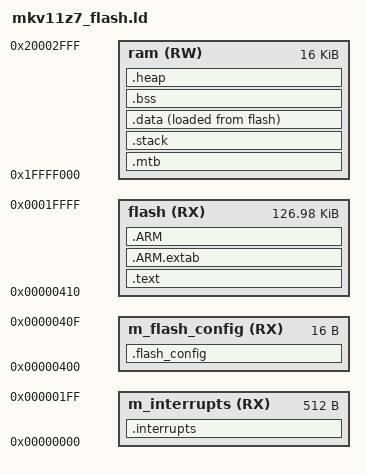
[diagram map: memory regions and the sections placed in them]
/*
** ###################################################################
**     Processors:          MKV11Z128VFM7
**                          MKV11Z128VLC7
**                          MKV11Z128VLF7
**                          MKV11Z128VLH7
**
**     Compiler:            GNU C Compiler
**     Reference manual:    KV11P64M75RM Rev.2, April 2015
**     Version:             rev. 1.0, 2014-12-14
**     Build:               b180911
**
**     Abstract:
**         Linker file for the GNU C Compiler
**
**     Copyright 2016 Freescale Semiconductor, Inc.
**     Copyright 2016-2018 NXP
**     All rights reserved.
**
**     Redistribution and use in source and binary forms, with or without modification,
**     are permitted provided that the following conditions are met:
**
**     1. Redistributions of source code must retain the above copyright notice, this list
**       of conditions and the following disclaimer.
**
**     2. Redistributions in binary form must reproduce the above copyright notice, this
**       list of conditions and the following disclaimer in the documentation and/or
**       other materials provided with the distribution.
**
**     3. Neither the name of the copyright holder nor the names of its
**       contributors may be used to endorse or promote products derived from this
**       software without specific prior written permission.
**
**     THIS SOFTWARE IS PROVIDED BY THE COPYRIGHT HOLDERS AND CONTRIBUTORS "AS IS" AND
**     ANY EXPRESS OR IMPLIED WARRANTIES, INCLUDING, BUT NOT LIMITED TO, THE IMPLIED
**     WARRANTIES OF MERCHANTABILITY AND FITNESS FOR A PARTICULAR PURPOSE ARE
**     DISCLAIMED. IN NO EVENT SHALL THE COPYRIGHT HOLDER OR CONTRIBUTORS BE LIABLE FOR
**     ANY DIRECT, INDIRECT, INCIDENTAL, SPECIAL, EXEMPLARY, OR CONSEQUENTIAL DAMAGES
**     (INCLUDING, BUT NOT LIMITED TO, PROCUREMENT OF SUBSTITUTE GOODS OR SERVICES;
**     LOSS OF USE, DATA, OR PROFITS; OR BUSINESS INTERRUPTION) HOWEVER CAUSED AND ON
**     ANY THEORY OF LIABILITY, WHETHER IN CONTRACT, STRICT LIABILITY, OR TORT
**     (INCLUDING NEGLIGENCE OR OTHERWISE) ARISING IN ANY WAY OUT OF THE USE OF THIS
**     SOFTWARE, EVEN IF ADVISED OF THE POSSIBILITY OF SUCH DAMAGE.
**
**     http:                 www.nxp.com
**     mail:                 support@nxp.com
**
** ###################################################################
*/

/* Entry Point */
ENTRY(Power_On_Reset)

HEAP_SIZE  = DEFINED(__heap_size__)  ? __heap_size__  : 0x0000;
STACK_SIZE = DEFINED(__stack_size__) ? __stack_size__ : 0x0400;

/* Specify the memory areas */
MEMORY
{
  m_interrupts          (RX)  : ORIGIN = 0x00000000, LENGTH = 0x00000200
  m_flash_config        (RX)  : ORIGIN = 0x00000400, LENGTH = 0x00000010
  flash                 (RX)  : ORIGIN = 0x00000410, LENGTH = 0x0001FBF0
  ram                   (RW)  : ORIGIN = 0x1FFFF000, LENGTH = 0x00004000
}

/* Define output sections */
SECTIONS
{
  /* The startup code goes first into internal flash */
  .interrupts :
  {
    . = ALIGN(4);
    KEEP(*(.interupt_vector))     /* Startup code */
    . = ALIGN(4);
  } > m_interrupts

  .flash_config :
  {
    . = ALIGN(4);
    KEEP(*(.FlashConfig))    /* Flash Configuration Field (FCF) */
    . = ALIGN(4);
  } > m_flash_config

  /* The program code and other data goes into internal flash */
  .text :
  {
    . = ALIGN(4);
    *(.text)                 /* .text sections (code) */
    *(.text*)                /* .text* sections (code) */
    *(.rodata)               /* .rodata sections (constants, strings, etc.) */
    *(.rodata*)              /* .rodata* sections (constants, strings, etc.) */
    *(.glue_7)               /* glue arm to thumb code */
    *(.glue_7t)              /* glue thumb to arm code */
    *(.eh_frame)
    KEEP (*(.init))
    KEEP (*(.fini))
    . = ALIGN(4);
  } > flash 

  .ARM.extab :
  {
    *(.ARM.extab* .gnu.linkonce.armextab.*)
  } > flash 

  .ARM :
  {
    __exidx_start = .;
    *(.ARM.exidx*)
    __exidx_end = .;
  } > flash 


  __etext = .;    /* define a global symbol at end of code */
  __DATA_ROM = .; /* Symbol is used by startup for data initialization */

  /* reserve MTB memory at the beginning of ram    */
  .mtb : /* MTB buffer address as defined by the hardware */
  {
    . = ALIGN(8);
    _mtb_start = .;
    KEEP(*(.mtb_buf)) /* need to KEEP Micro Trace Buffer as not referenced by application */
    . = ALIGN(8);
    _mtb_end = .;
  } > ram   

  .stack :
  {
    . = ALIGN(8);
    . += STACK_SIZE;
    _stack_top = .;
  } > ram   

  .data :
  {
    . = ALIGN(4);
    _data_load_addr = LOADADDR (.data);
    _data_start = .;      /* create a global symbol at data start */
    *(.data)                 /* .data sections */
    *(.data*)                /* .data* sections */
    KEEP(*(.jcr*))
    . = ALIGN(4);
    _data_end = .;        /* define a global symbol at data end */
  } >ram AT>flash

  __DATA_END = __DATA_ROM + (_data_end - _data_start);
  text_end = ORIGIN(flash ) + LENGTH(flash );
  ASSERT(__DATA_END <= text_end, "region flash  overflowed with text and data")

  /* Uninitialized data section */
  .bss :
  {
    /* This is used by the startup in order to initialize the .bss section */
    . = ALIGN(4);
    __START_BSS = .;
    _bss_start = .;
    *(.bss)
    *(.bss*)
    *(COMMON)
    . = ALIGN(4);
    _bss_end = .;
    __END_BSS = .;
  } > ram   

  .heap :
  {
    . = ALIGN(8);
    __end__ = .;
    PROVIDE(end = .);
    __HeapBase = .;
    . += HEAP_SIZE;
    __HeapLimit = .;
    __heap_limit = .; /* Add for _sbrk */
  } > ram   


  /* Initializes stack on the end of block */
  __StackTop   = ORIGIN(ram   ) + LENGTH(ram   );
  __StackLimit = __StackTop - STACK_SIZE;
  PROVIDE(__stack = __StackTop);

  .ARM.attributes 0 : { *(.ARM.attributes) }

  ASSERT(__StackLimit >= __HeapLimit, "region ram    overflowed with stack and heap")
}

